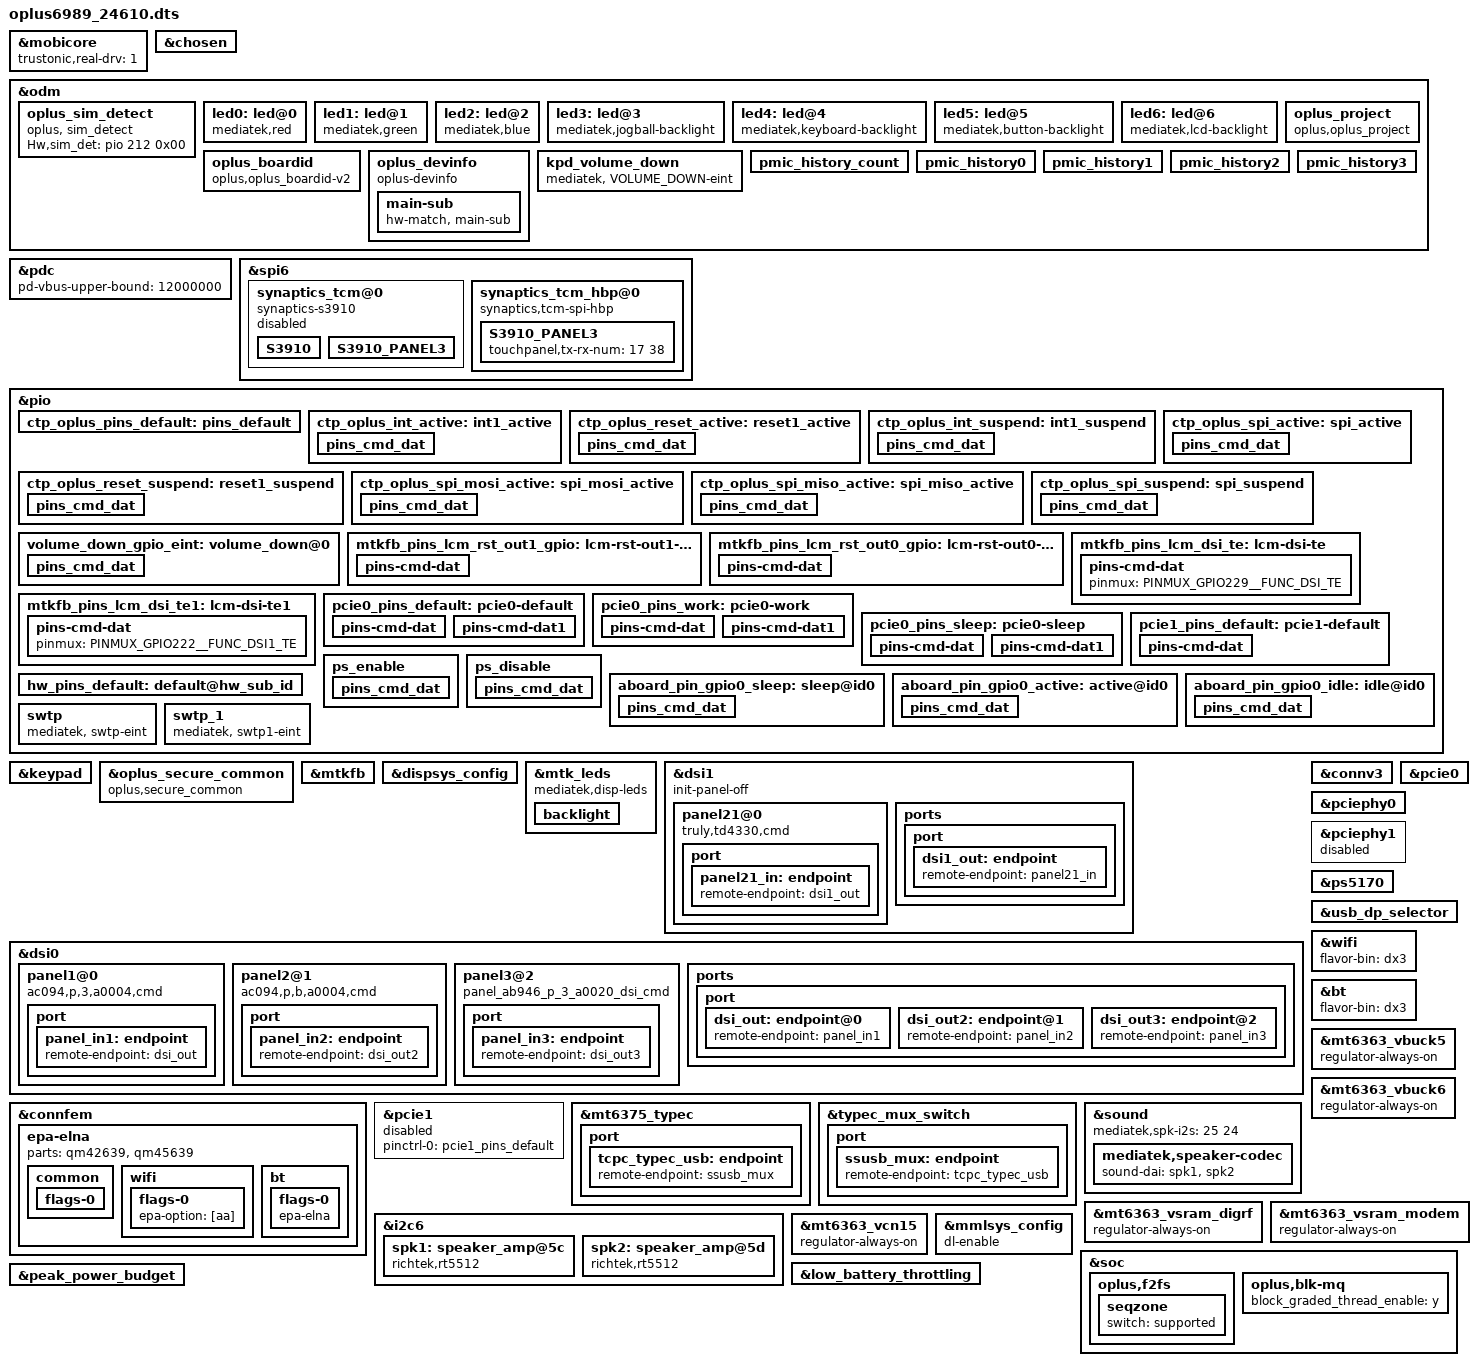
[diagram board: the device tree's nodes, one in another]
// SPDX-License-Identifier: (GPL-2.0 OR MIT)
/*
 * Copyright (C) 2022 MediaTek Inc.
 */
/dts-v1/;
/plugin/;
#include <dt-bindings/interrupt-controller/arm-gic.h>
#include <dt-bindings/interrupt-controller/irq.h>
#include <dt-bindings/pinctrl/mt6989-pinfunc.h>
#include <dt-bindings/phy/phy.h>
//#ifdef OPLUS_BUG_STABILITY
//NFC dtsi
#include "mediatek/nfc/mt6989_24610_sn220.dtsi"
//endif OPLUS_BUG_STABILITY

/* #ifdef OPLUS_FEATURE_CHG_BASIC */
/* Add for DX-3 charge device-tree */
#include "mediatek/oplus_misc_24610.dtsi"
/* #endif */

//#ifdef OPLUS_FEATURE_SENSOR
#include "mediatek/oplus_sensor_24610.dtsi"
//#endif

/* #ifdef OPLUS_FEATURE_CHG_BASIC */
#include "mediatek/oplus_charge_24610.dtsi"
/* #endif */

/* Trustonic Mobilecore real driver */
&mobicore{
        trustonic,real-drv = <1>;
};

/* Add for Cayman(24610) fingerprint device-tree */
/* #ifdef CONFIG_UFF_FINGERPRINT */
#include "mediatek/oplus_uff_24610.dtsi"
/* #endif CONFIG_UFF_FINGERPRINT */

&chosen {
bootargs_ext = "kmemleak=off kasan=off \
loglevel=8 initcall_debug=1 \
log_buf_len=2m \
arm64.nopauth arm64.nosme arm64.nosve";
};

&odm {
/* Add for sim detect */
    oplus_sim_detect {
        compatible = "oplus, sim_detect";
        Hw,sim_det = <&pio 212 0x00>;
    };
};

/* #ifdef OPLUS_DISPLAY_FEATURE */
&odm {
	led0:led@0 {
		compatible = "mediatek,red";
		led_mode = <0>;
		data = <1>;
		pwm_config = <0 0 0 0 0>;
	};
	led1:led@1 {
		compatible = "mediatek,green";
		led_mode = <0>;
		data = <1>;
		pwm_config = <0 0 0 0 0>;
	};
	led2:led@2 {
		compatible = "mediatek,blue";
		led_mode = <0>;
		data = <1>;
		pwm_config = <0 0 0 0 0>;
	};
	led3:led@3 {
		compatible = "mediatek,jogball-backlight";
		led_mode = <0>;
		data = <1>;
		pwm_config = <0 0 0 0 0>;
	};
	led4:led@4 {
		compatible = "mediatek,keyboard-backlight";
		led_mode = <0>;
		data = <1>;
		pwm_config = <0 0 0 0 0>;
	};
	led5:led@5 {
		compatible = "mediatek,button-backlight";
		led_mode = <0>;
		data = <1>;
		pwm_config = <0 0 0 0 0>;
	};
	led6:led@6 {
		compatible = "mediatek,lcd-backlight";
		led_mode = <4>;
		data = <1>;
		pwm_config = <0 1 0 0 0>;
	};
};

&pdc {
	pd-vbus-upper-bound = <12000000>;
};


&spi6 {
	status = "okay";
	#address-cells = <1>;
	#size-cells = <0>;

	synaptics_tcm@0{
		compatible = "synaptics-s3910";
		reg = <0x0>;
		chip-name = "S3910";
		status = "disabled";
		spi-max-frequency = <19000000>;
		/* Interrupt && Irq-gpio */
		interrupt-parent = <&pio>;
		interrupts = <6 0x2008>;

		/* Power Config */
		/* enable2v8_gpio  = <&pio 164 0x1>; */
		vdd_2v8-supply = <&mt6373_vtp>;
		vdd_2v8_volt = <3000000>;
		/* vcc_1v8-supply  = <&mt6373_vmc>; */
		/* vcc_1v8_volt = <1800000>; */

		/* Other HW Resource */

		irq-gpio = <&pio 6 0x2008>;
		reset-gpio = <&pio 3 0x1>;
		//cs-gpio = <&pio 110 0x00>;

		pinctrl-names = "default",  "oplus_int_active",
		"oplus_reset_active", "oplus_int_suspend",
		"oplus_reset_suspend", "oplus_spi_active",
		"oplus_spi_suspend";
		pinctrl-0 = <&ctp_oplus_pins_default>;
		pinctrl-1 = <&ctp_oplus_int_active>;
		pinctrl-2 = <&ctp_oplus_reset_active>;
		pinctrl-3 = <&ctp_oplus_int_suspend>;
		pinctrl-4 = <&ctp_oplus_reset_suspend>;
		pinctrl-5 = <&ctp_oplus_spi_active>, <&ctp_oplus_spi_mosi_active>;
		pinctrl-6 = <&ctp_oplus_spi_suspend>;

		touchpanel,max-num-support = <10>;
		touchpanel,tx-rx-num = <18 39>;
		touchpanel,panel-coords = <12640 27800>;
		touchpanel,display-coords = <1264 2780>;
		touchpanel,touchmajor-limit = <128 216>;
		touchpanel,elimination-range = <20 200 200>;
		touchpanel,int-mode = <1>; /*0: interrupt and disable, 1:interrupt and not disable*/
		touchpanel,smooth-level = <0 1 2 4 7 9>;
		touchpanel,smooth-level-charging = <0 2 4 7 8 9>;
		touchpanel,sensitive-level = <0 70 55 40 25 10>;
		touchpanel,single-optimized-time = <8>;
		touchpanel,high-frame-rate-time = <60>;

		vid_len = <2>;
		panel_type = <7 3>; /*type:7 TIANMA*/
		platform_support_project = <24610 24708>;
		platform_support_project_dir = <24610 24610>;
		platform_support_project_commandline = "panel_ab948_p_7_a0020_dsi_cmd", "panel_ab946_p_3_a0020_dsi_cmd";

		prevention,curved_screen_V2;
		prevention,grip_disable_level = <6>;
		prevention,updelay_time_ms = <30>;
		prevention,makeup_cnt_weight = <4 1 2 2 2>;
		prevention,large_corner_range = <1380 3400>;
		prevention,large_corner_judge_condition = <500 300 1000 7 7>;
		prevention,trx_reject_condition = <8 7 7>;
		prevention,trx_strict_reject_condition = <8 6 6>;
		prevention,large_judge_time_ms = <500 50 30>;
		prevention,large_exit_condition = <8 8 2>;
		prevention,single_channel_width = <320 320>;
		prevention,normal_tap_condition = <10 350>;
		prevention,long_edge_condition = <179 90 120 80>;
		prevention,long_strict_edge_condition = <160 60>;
		prevention,long_fingerhold_condition = <70 6 4 4>;
		prevention,short_edge_condition = <179 90 120 80>;
		prevention,short_strict_edge_condition = <160 60>;
		prevention,large_strict_exit_condition = <6 6>;
		prevention,top_corner_config = <250 750 1000>;
		prevention,edge_swipe_config = <340 1130>;

		prevention,curved_screen_V4;
		prevention,long_eliminate_point_type = <2 12400 9240 240 27720 300 1>;
		prevention,long_fingerhold_condition2 = <700 2000 0 0>;
		prevention,top_corner_config2 =<3 80 600 1500 0>;
		prevention,hor_long_top_corner_config =<300 2000 0 0>;
		prevention,top_middle_config =<12400 1000 1000 0>;
		prevention,corner_eliminate_point_type =<0 1380 2270 1>;
		prevention,finger_hold_differ_size = <1 0 400 300>;
		prevention,finger_hold_max_rx_exit_distance = <5 350 2300>;
		prevention,max_rx_exit_distance = <1 5 150 350 2000>;
		prevention,dynamic_finger_hold_exit_distance = <1 350 2300 450>;
		prevention,edge_sliding_matched_support = <1 150 3 0>;

		//grip v4.2 reclining mode
		prevention,reclining_mode_support = <1>;
		prevention,long_eliminate_point_type_recli = <2 12400 9240 240 27720 500 1>;
		prevention,finger_hold_differ_size_recli = <1 0 400 400>;
		prevention,finger_hold_max_rx_exit_distance_recli = <5 350 2300>;
		prevention,max_rx_exit_distance_recli = <1 5 100 350 2300>;
		prevention,dynamic_finger_hold_exit_distance_recli = <1 350 2300 450>;
		prevention,edge_sliding_matched_support_recli = <1 150 3 0>;
		prevention,long_edge_condition_recli = <179 90 120 80>;

		/* SW Support Feature Control */
		black_gesture_support;
		sportify_aod_gesture_support;
		pressure_report_support;
		charger_pump_support;
		game_switch_support;
		glove_mode_support;
		smart_gesture_support;
		fw_update_app_support;
		fingerprint_underscreen_support;
		freq_hop_simulate_support;
		report_flow_unlock_support;
		screenoff_fingerprint_info_support;
		irq_need_dev_resume_ok;
		enable_point_auto_change;
		kernel_grip_support;
		//grip_no_driver_support;
		health_monitor_support;
		black_gesture_indep_support;
		snr_read_support;
		palm_to_sleep_support;
		exception_upload_support;
		tp_data_record_support;
		fingerprint_not_report_in_suspend;
		/*
		 *Virtual Key Config:
		 *1:touchpanel,button-type: <virtualkey_type  supportted_button-map>
		 *virtualkey_type:
		 *Type 1: using board_properties
		 *Type 2: using same IC (button zone&& touch zone are seprate)
		 *Type 3: using diffrent IC (button zone&& touch zone are seprate)
		 *Type 4: No need of virtual key process
		 *supportted_button-map:select|menu|home|back
		 *
		 *2:touchpanel,button-map
		 *type (X1,Y1)(X2,Y2)(X3,Y3)(Width_X,Hight_Y)--Only when button-type is 0
		 */
		touchpanel,button-type = <4>;
		touchpanel.button-TRx = <0 0>;

		S3910 {
			switch_report_rate;
			report_rate_default = <60>;
			report_rate_game_value = <0x03>;
			fps_report_rate = <60 2 90 3 120 3>;//1:360Hz 2:125Hz 3:240Hz
			fwupdate_bootloader = <1>;
			normal_config_version = <2>;
			default_gesture_mask = <8191>;
		};
		S3910_PANEL3 {
			interrupt-parent = <&pio>;
			interrupts = <6 0x2008>;

			/* Power Config */
			/* enable2v8_gpio  = <&pio 164 0x1>; */
			vdd_2v8-supply = <&mt6373_vtp>;
			vdd_2v8_volt = <3000000>;
			/* vcc_1v8-supply  = <&mt6373_vmc>; */
			/* vcc_1v8_volt = <1800000>; */

			/* Other HW Resource */

			irq-gpio = <&pio 6 0x2008>;
			reset-gpio = <&pio 3 0x1>;
			//cs-gpio = <&pio 110 0x00>;

			pinctrl-names = "default",  "oplus_int_active",
			"oplus_reset_active", "oplus_int_suspend",
			"oplus_reset_suspend", "oplus_spi_active",
			"oplus_spi_suspend";
			pinctrl-0 = <&ctp_oplus_pins_default>;
			pinctrl-1 = <&ctp_oplus_int_active>;
			pinctrl-2 = <&ctp_oplus_reset_active>;
			pinctrl-3 = <&ctp_oplus_int_suspend>;
			pinctrl-4 = <&ctp_oplus_reset_suspend>;
			pinctrl-5 = <&ctp_oplus_spi_active>, <&ctp_oplus_spi_mosi_active>;
			pinctrl-6 = <&ctp_oplus_spi_suspend>;

			touchpanel,max-num-support = <10>;
			touchpanel,tx-rx-num = <17 38>;
			touchpanel,panel-coords = <12640 27800>;
			touchpanel,display-coords = <1264 2780>;
			touchpanel,touchmajor-limit = <128 216>;
			touchpanel,elimination-range = <20 200 200>;
			touchpanel,int-mode = <1>; /*0: interrupt and disable, 1:interrupt and not disable*/
			touchpanel,smooth-level = <0 1 2 4 7 9>;
			touchpanel,smooth-level-charging = <0 2 4 7 8 9>;
			touchpanel,sensitive-level = <0 70 55 40 25 10>;
			touchpanel,single-optimized-time = <8>;
			touchpanel,high-frame-rate-time = <60>;

			prevention,curved_screen_V2;
			prevention,grip_disable_level = <6>;
			prevention,updelay_time_ms = <30>;
			prevention,makeup_cnt_weight = <4 1 2 2 2>;
			prevention,large_corner_range = <1380 3400>;
			prevention,large_corner_judge_condition = <500 300 1000 7 7>;
			prevention,trx_reject_condition = <8 7 7>;
			prevention,trx_strict_reject_condition = <8 6 6>;
			prevention,large_judge_time_ms = <500 50 30>;
			prevention,large_exit_condition = <8 8 2>;
			prevention,single_channel_width = <320 320>;
			prevention,normal_tap_condition = <10 350>;
			prevention,long_edge_condition = <179 90 120 80>;
			prevention,long_strict_edge_condition = <160 60>;
			prevention,long_fingerhold_condition = <70 6 4 4>;
			prevention,short_edge_condition = <179 90 120 80>;
			prevention,short_strict_edge_condition = <160 60>;
			prevention,large_strict_exit_condition = <6 6>;
			prevention,top_corner_config = <250 750 1000>;
			prevention,edge_swipe_config = <340 1130>;

			prevention,curved_screen_V4;
			prevention,long_eliminate_point_type = <2 12400 9240 240 27720 300 1>;
			prevention,long_fingerhold_condition2 = <700 2000 0 0>;
			prevention,top_corner_config2 =<3 80 600 1500 0>;
			prevention,hor_long_top_corner_config =<300 2000 0 0>;
			prevention,top_middle_config =<12400 1000 1000 0>;
			prevention,corner_eliminate_point_type =<0 1380 2270 1>;
			prevention,finger_hold_differ_size = <1 0 400 300>;
			prevention,finger_hold_max_rx_exit_distance = <5 350 2300>;
			prevention,max_rx_exit_distance = <1 5 150 350 2000>;
			prevention,dynamic_finger_hold_exit_distance = <1 350 2300 450>;
			prevention,edge_sliding_matched_support = <1 150 3 0>;
		};
	};

	synaptics_tcm_hbp@0{
		compatible = "synaptics,tcm-spi-hbp";
		reg = <0x0>;
		chip-name = "S3910";
		status = "okay";
		spi-max-frequency = <19000000>;

		/* Interrupt && Irq-gpio */
		interrupt-parent = <&pio>;
		interrupts = <6 0x2008>;

		/* Power Config */
		/* enable2v8_gpio  = <&pio 164 0x1>; */
		/* synaptics,avdd-gpio = <&pio 186 0x1>; */
		avdd-supply = <&mt6373_vtp>;
		synaptics,avdd-name = "avdd";
		/* vcc_1v8-supply  = <&mt6373_vmc>; */
		/* vcc_1v8_volt = <1800000>; */



		/* Other HW Resource */

		synaptics,irq-gpio = <&pio 6 0x2008>;
		synaptics,reset-gpio = <&pio 3 0x1>;
		//cs-gpio = <&pio 110 0x00>;


		pinctrl-names = "default", "ts_spi_active", "ts_spi_suspend";
		pinctrl-0 = <&ctp_oplus_pins_default>;
		pinctrl-1 = <&ctp_oplus_int_active &ctp_oplus_reset_active &ctp_oplus_spi_active &ctp_oplus_spi_mosi_active &ctp_oplus_spi_miso_active>;
		pinctrl-2 = <&ctp_oplus_int_suspend &ctp_oplus_reset_suspend &ctp_oplus_spi_suspend>;

		touchpanel,max-num-support = <10>;
		touchpanel,tx-rx-num = <18 39>;
		touchpanel,panel-coords = <20224 44480>;
		vid_len = <2>;
		panel_type = <7 3>; /*type:7 TIANMA*/
		platform_support_project = <24610 24708>;
		platform_support_project_dir = <24610 24610>;
		platform_support_project_commandline = "panel_ab948_p_7_a0020_dsi_cmd", "panel_ab946_p_3_a0020_dsi_cmd";

		synaptics,power-on-state = <1>;
		synaptics,power-delay-ms = <200>;
		synaptics,irq-on-state = <0>;
		synaptics,reset-on-state = <0>;
		synaptics,reset-active-ms = <10>;
		synaptics,reset-delay-ms = <80>;
		synaptics,spi-mode = <0>;
		synaptics,spi-byte-delay-us = <0>;
		synaptics,spi-block-delay-us = <0>;

		stats_upload_support;

		S3910_PANEL3 {
			touchpanel,tx-rx-num = <17 38>;
		};
	};
};

/*add for nvwa TP*/
&pio {
	ctp_oplus_pins_default: pins_default {
	};
	ctp_oplus_int_active: int1_active {
		pins_cmd_dat {
			pinmux = <PINMUX_GPIO6__FUNC_GPIO6>;
			bias-disable;
			input-enable;
		};
	};
	ctp_oplus_reset_active: reset1_active {
		pins_cmd_dat {
			pinmux = <PINMUX_GPIO3__FUNC_GPIO3>;
			output-high;
		};
	};
	ctp_oplus_int_suspend: int1_suspend {
		pins_cmd_dat {
			pinmux = <PINMUX_GPIO6__FUNC_GPIO6>;
			output-low;
		};
	};
	ctp_oplus_reset_suspend: reset1_suspend {
		pins_cmd_dat {
			pinmux = <PINMUX_GPIO3__FUNC_GPIO3>;
			output-low;
		};
	};
	ctp_oplus_spi_active: spi_active {
		pins_cmd_dat {
			pinmux = <PINMUX_GPIO232__FUNC_SPI6_B_CSB>,
				<PINMUX_GPIO231__FUNC_SPI6_B_CLK>;
			bias-disable;
			drive-strength = <2>;
		};
	};
	ctp_oplus_spi_mosi_active: spi_mosi_active {
		pins_cmd_dat {
			pinmux = <PINMUX_GPIO233__FUNC_SPI6_B_MO>;
			bias-disable;
			drive-strength = <3>;
		};
	};
	ctp_oplus_spi_miso_active: spi_miso_active {
		pins_cmd_dat {
			pinmux = <PINMUX_GPIO234__FUNC_SPI6_B_MI>;
			bias-disable;
			drive-strength = <2>;
		};
	};
	ctp_oplus_spi_suspend: spi_suspend {
		pins_cmd_dat {
			pinmux = < PINMUX_GPIO234__FUNC_GPIO234>,
				< PINMUX_GPIO232__FUNC_GPIO232>,
				<PINMUX_GPIO233__FUNC_GPIO233>,
				< PINMUX_GPIO231__FUNC_GPIO231>;
			bias-disable;
			output-low;
			drive-strength = <4>;
		};
	};
};


&keypad {
        keypad,volume-down = <&pio 11 0x00>;
        pinctrl-names = "volume_down_as_int";
        pinctrl-0 = <&volume_down_gpio_eint>;
        status = "okay";
};

&pio {
        volume_down_gpio_eint:volume_down@0{
                pins_cmd_dat {
                        pinmux = <PINMUX_GPIO11__FUNC_GPIO11>;
                        slew-rate = <0>;  /*direction 0:in, 1:out*/
                        input-enable;
                        bias-disable;
                };
        };
};

&oplus_secure_common {
    compatible = "oplus,secure_common";
    oplus,sec_reg_num = <0>;
    oplus,sec_en_anti_reg = <0>;
    oplus,sec_override1_reg = <0>;
    oplus,override1_en_value = <0>;
};

&pio {
	mtkfb_pins_lcm_rst_out1_gpio: lcm-rst-out1-gpio {
		pins-cmd-dat {
			pinmux = <PINMUX_GPIO230__FUNC_GPIO230>;
			slew-rate = <1>;
			output-high;
		};
	};

	mtkfb_pins_lcm_rst_out0_gpio: lcm-rst-out0-gpio {
		pins-cmd-dat {
			pinmux = <PINMUX_GPIO230__FUNC_GPIO230>;
			slew-rate = <1>;
			output-low;
		};
	};
	mtkfb_pins_lcm_dsi_te: lcm-dsi-te {
		pins-cmd-dat {
			pinmux = <PINMUX_GPIO229__FUNC_DSI_TE>;
		};
	};

	mtkfb_pins_lcm_dsi_te1: lcm-dsi-te1 {
		pins-cmd-dat {
			pinmux = <PINMUX_GPIO222__FUNC_DSI1_TE>;
		};
	};

};

&mtkfb {
	pinctrl-names = "lcm_rst_out1_gpio", "lcm_rst_out0_gpio",
		"mode_te_te", "mode_te_te1";
	pinctrl-0 = <&mtkfb_pins_lcm_rst_out1_gpio>;
	pinctrl-1 = <&mtkfb_pins_lcm_rst_out0_gpio>;
	pinctrl-2 = <&mtkfb_pins_lcm_dsi_te>;
	pinctrl-3 = <&mtkfb_pins_lcm_dsi_te1>;

	status = "okay";
};

&dispsys_config {
	pinctrl-names = "mode_te_te", "mode_te_te1";
	pinctrl-0 = <&mtkfb_pins_lcm_dsi_te>;
	pinctrl-1 = <&mtkfb_pins_lcm_dsi_te1>;
	status = "okay";
};

/*  OPLUS_DISPLAY_FEATURE */
&mtk_leds {
	compatible = "mediatek,disp-leds";
	status = "okay";

	backlight {
		label = "lcd-backlight";
		led_mode = <4>;
		min-brightness = <1>;
		max-brightness = <4094>;
		max-hw-brightness = <4094>;
		led-bits = <13>;
		trans-bits = <13>;
		default-state = "on";
	};
};
/*  OPLUS_DISPLAY_FEATURE */

&dsi1 {
//	status = "okay";
	#address-cells = <1>;
	#size-cells = <0>;
	init-panel-off;
	panel21@0 {
		compatible = "truly,td4330,cmd";
		reg = <1>;
		pm-enable-gpios = <&pio 215 0>;
		reset-gpios = <&pio 230 0>;
		gate-ic = <4831>;
		pinctrl-names = "default";
		port {
			panel21_in: endpoint {
				remote-endpoint = <&dsi1_out>;
			};
		};
	};
	ports {
		port {
			dsi1_out: endpoint {
				remote-endpoint = <&panel21_in>;
			};
		};
	};
};

&dsi0 {
	status = "okay";
	#address-cells = <1>;
	#size-cells = <0>;
	/** #ifdef OPLUS_DISPLAY_FEATURE **/
	panel1@0 {
		compatible = "ac094,p,3,a0004,cmd";
		reg = <0>;
		pm-enable-gpios = <&pio 86 0>;
		reset-gpios = <&pio 230 0>;
		1p8-supply = <&mt6373_vrfio18_aif>;
		3p0-supply = <&mt6373_vmc>;
		oplus,dsi-serial-number-enabled=<1>;
		oplus,dsi-serial-number-switch-page;
		oplus,dsi-serial-number-index= <0>;
		oplus,dsi-serial-number-switch-page-command= <0xFF 0x08 0x38 0x1D>;
		oplus,dsi-serial-number-default-switch-page-command= <0xFF 0x08 0x38 0x00>;
		oplus,dsi-serial-number-reg= <0x82>;
		oplus,dsi-serial-number-read-count= <7>;
		oplus,panel-max-brightness=<4094>;
		/* 0 not support, 1 with switch, 2 Global high frequency pwm without switch */
		oplus,pwm-turbo-support = <2>;
		oplus,pwm-switch-backlight-threshold = <0x43F>;
		oplus,pwm-onepulse-support = <1>;
		oplus,pwm-onepulse-enabled = <0>;
		oplus,pwm-turbo-wait-te = <1>;
		oplus-adfr-config = <0x201>;
		oplus-adfr-test-te-gpios = <&pio 222 0>;
		/* ofp config */
		oplus,ofp-fp-type = <0x10>;
		oplus,ofp-fp-type-compatible-mode;
		oplus,ofp-need-to-update-lhbm-pressed-icon-gamma;
		oplus,ofp-lhbm-dbv-alpha-cmd-index = <1>;
		oplus,ofp-lhbm-dbv-alpha-register-offset = <1>;
		oplus,ofp-lhbm-dbv-alpha-value = <
			/* lhbm dbv alpha value from 0 to 1087 */
			0x0CC 0x0CC 0x0CC 0x0CC 0x0CC 0x0CC 0x0CC 0x0CC 0x0CC 0x0CC 0x0CC 0x0CC 0x0CC 0x0CC 0x0CC 0x0CC 0x0CC 0x0CC 0x0CC 0x0CC
			0x0CC 0x0CC 0x0CC 0x0CC 0x0CC 0x0CC 0x0CC 0x0CC 0x0CC 0x0CC 0x0CC 0x0CC 0x0CC 0x0CC 0x0CC 0x0CC 0x0CC 0x0CC 0x0CC 0x0CC
			0x0CC 0x0CD 0x0CD 0x0CE 0x0CE 0x0CF 0x0D0 0x0D0 0x0D0 0x0D1 0x0D0 0x0D1 0x0D2 0x0D2 0x0D2 0x0D3 0x0D3 0x0D4 0x0D4 0x0D4
			0x0D4 0x0D5 0x0D5 0x0D5 0x0D6 0x0D6 0x0D6 0x0D6 0x0D7 0x0D7 0x0D7 0x0D8 0x0D9 0x0D9 0x0D9 0x0DA 0x0DA 0x0DA 0x0DB 0x0DB
			0x0DC 0x0DC 0x0DD 0x0DD 0x0DE 0x0DE 0x0DE 0x0DE 0x0DF 0x0DF 0x0E0 0x0E0 0x0E1 0x0E1 0x0E2 0x0E2 0x0E3 0x0E3 0x0E3 0x0E4
			0x0E4 0x0E5 0x0E5 0x0E5 0x0E6 0x0E6 0x0E6 0x0E7 0x0E7 0x0E8 0x0E8 0x0E9 0x0E9 0x0E9 0x0EA 0x0EA 0x0EA 0x0EB 0x0EB 0x0EC
			0x0EC 0x0ED 0x0ED 0x0EE 0x0EE 0x0EF 0x0EF 0x0EF 0x0F0 0x0F0 0x0F1 0x0F2 0x0F1 0x0F2 0x0F3 0x0F3 0x0F4 0x0F4 0x0F5 0x0F5
			0x0F6 0x0F6 0x0F7 0x0F7 0x0F8 0x0F8 0x0F8 0x0F9 0x0F9 0x0FA 0x0FA 0x0FB 0x0FC 0x0FC 0x0FC 0x0FD 0x0FD 0x0FD 0x0FD 0x0FF
			0x0FF 0x100 0x101 0x101 0x101 0x102 0x102 0x102 0x102 0x104 0x104 0x104 0x105 0x105 0x106 0x107 0x108 0x108 0x107 0x109
			0x109 0x109 0x10A 0x10B 0x10B 0x10C 0x10C 0x10C 0x10E 0x10E 0x10E 0x10F 0x110 0x110 0x111 0x111 0x111 0x111 0x112 0x113
			0x114 0x115 0x115 0x115 0x116 0x116 0x117 0x116 0x118 0x119 0x119 0x119 0x11A 0x11A 0x11B 0x11C 0x11D 0x11B 0x11E 0x11E
			0x11E 0x11F 0x11F 0x120 0x120 0x121 0x122 0x122 0x123 0x124 0x124 0x125 0x125 0x126 0x126 0x127 0x126 0x128 0x129 0x129
			0x12A 0x12A 0x12B 0x12C 0x12C 0x12D 0x12C 0x12E 0x12F 0x12F 0x130 0x130 0x131 0x132 0x132 0x133 0x132 0x134 0x134 0x134
			0x135 0x135 0x136 0x137 0x137 0x137 0x137 0x13A 0x13A 0x13B 0x13C 0x13C 0x13C 0x13D 0x13D 0x13D 0x13F 0x140 0x140 0x141
			0x143 0x143 0x143 0x144 0x144 0x144 0x146 0x147 0x147 0x148 0x149 0x149 0x149 0x14B 0x14C 0x14B 0x14C 0x14D 0x14E 0x14F
			0x150 0x150 0x151 0x151 0x152 0x151 0x154 0x155 0x155 0x156 0x157 0x157 0x158 0x159 0x159 0x158 0x15B 0x15B 0x15B 0x15C
			0x15E 0x15F 0x15E 0x160 0x15F 0x161 0x161 0x163 0x163 0x164 0x164 0x166 0x166 0x168 0x168 0x169 0x16A 0x16A 0x16B 0x16B
			0x16C 0x16D 0x16E 0x16E 0x16E 0x16F 0x171 0x172 0x173 0x173 0x174 0x174 0x175 0x175 0x176 0x178 0x178 0x179 0x179 0x17B
			0x17C 0x17D 0x17D 0x17E 0x17E 0x180 0x181 0x181 0x181 0x182 0x183 0x184 0x184 0x185 0x187 0x189 0x189 0x18A 0x18A 0x18B
			0x18C 0x18D 0x18D 0x18D 0x18E 0x190 0x191 0x193 0x193 0x194 0x194 0x195 0x196 0x196 0x198 0x198 0x199 0x199 0x19A 0x19D
			0x19D 0x19D 0x19F 0x19F 0x1A0 0x1A1 0x1A1 0x1A2 0x1A3 0x1A4 0x1A4 0x1A5 0x1A6 0x1A7 0x1A9 0x1A9 0x1A9 0x1AA 0x1AD 0x1AD
			0x1AE 0x1AD 0x1AF 0x1B0 0x1B0 0x1B0 0x1B2 0x1B2 0x1B2 0x1B3 0x1B6 0x1B6 0x1B7 0x1B7 0x1B8 0x1B9 0x1B9 0x1B8 0x1BA 0x1BC
			0x1BC 0x1BD 0x1BE 0x1BF 0x1BF 0x1C0 0x1C2 0x1C2 0x1C3 0x1C2 0x1C5 0x1C6 0x1C6 0x1C5 0x1C8 0x1CA 0x1CA 0x1CA 0x1CB 0x1CB
			0x1CC 0x1CD 0x1CF 0x1CF 0x1CF 0x1CF 0x1D1 0x1D2 0x1D3 0x1D3 0x1D5 0x1D6 0x1D6 0x1D7 0x1D7 0x1D8 0x1D9 0x1DA 0x1DA 0x1DB
			0x1DC 0x1DD 0x1DD 0x1E0 0x1E1 0x1E0 0x1E1 0x1E3 0x1E4 0x1E4 0x1E3 0x1E6 0x1E6 0x1E8 0x1E8 0x1E9 0x1E9 0x1EA 0x1EA 0x1ED
			0x1ED 0x1EE 0x1ED 0x1F0 0x1F1 0x1F2 0x1F2 0x1F3 0x1F4 0x1F5 0x1F6 0x1F6 0x1F7 0x1F7 0x1F9 0x1FB 0x1FB 0x1FC 0x1FB 0x1FE
			0x1FF 0x200 0x1FF 0x201 0x201 0x203 0x203 0x205 0x206 0x206 0x207 0x208 0x209 0x209 0x209 0x20A 0x20C 0x20D 0x20D 0x20D
			0x20F 0x211 0x211 0x212 0x213 0x214 0x214 0x215 0x216 0x217 0x218 0x219 0x21A 0x21B 0x21B 0x21B 0x21E 0x21E 0x21F 0x21F
			0x222 0x221 0x223 0x224 0x225 0x225 0x225 0x226 0x229 0x229 0x229 0x229 0x22B 0x22D 0x22E 0x22D 0x22E 0x22F 0x231 0x232
			0x234 0x235 0x235 0x236 0x238 0x238 0x239 0x239 0x23A 0x23C 0x23C 0x23B 0x23E 0x23F 0x241 0x242 0x240 0x243 0x244 0x246
			0x246 0x246 0x247 0x249 0x249 0x24A 0x24B 0x24C 0x24C 0x24F 0x250 0x251 0x250 0x252 0x253 0x255 0x254 0x256 0x257 0x258
			0x258 0x25B 0x25B 0x25B 0x25B 0x25D 0x25E 0x25F 0x25F 0x261 0x261 0x263 0x264 0x265 0x266 0x266 0x266 0x268 0x26A 0x26A
			0x26B 0x26D 0x26F 0x26F 0x270 0x271 0x272 0x272 0x272 0x274 0x276 0x277 0x277 0x279 0x27A 0x27A 0x27B 0x27C 0x27D 0x27F
			0x27E 0x280 0x281 0x281 0x283 0x283 0x285 0x285 0x285 0x287 0x289 0x289 0x289 0x28B 0x28C 0x28C 0x28D 0x28D 0x28E 0x28F
			0x290 0x291 0x292 0x293 0x295 0x294 0x295 0x297 0x296 0x298 0x29A 0x29A 0x29B 0x29B 0x29D 0x29E 0x29F 0x29F 0x2A0 0x2A1
			0x2A2 0x2A2 0x2A4 0x2A4 0x2A6 0x2A7 0x2A7 0x2A8 0x2A8 0x2A9 0x2AA 0x2AC 0x2AC 0x2AC 0x2AF 0x2B0 0x2B0 0x2B1 0x2B2 0x2B2
			0x2B4 0x2B5 0x2B6 0x2B7 0x2B8 0x2B8 0x2B8 0x2B9 0x2BA 0x2BC 0x2BC 0x2BD 0x2BE 0x2C0 0x2BF 0x2C2 0x2C1 0x2C3 0x2C4 0x2C4
			0x2C6 0x2C7 0x2C7 0x2C7 0x2C7 0x2CA 0x2CB 0x2CC 0x2CC 0x2CD 0x2CE 0x2CF 0x2D0 0x2D0 0x2D0 0x2D3 0x2D4 0x2D3 0x2D5 0x2D7
			0x2D7 0x2D9 0x2DA 0x2D8 0x2DB 0x2DC 0x2DC 0x2DD 0x2DF 0x2E0 0x2E1 0x2E1 0x2E2 0x2E2 0x2E3 0x2E4 0x2E6 0x2E6 0x2E7 0x2E9
			0x2EA 0x2EA 0x2EB 0x2EC 0x2EE 0x2EE 0x2EF 0x2EE 0x2F1 0x2F1 0x2F2 0x2F4 0x2F4 0x2F5 0x2F6 0x2F7 0x2F8 0x2F9 0x2FA 0x2FB
			0x2FD 0x2FD 0x2FC 0x2FF 0x300 0x2FF 0x2FF 0x2FF 0x2FF 0x303 0x305 0x306 0x307 0x308 0x309 0x308 0x308 0x30C 0x30C 0x30C
			0x30E 0x30F 0x310 0x311 0x312 0x312 0x313 0x313 0x314 0x315 0x317 0x318 0x318 0x318 0x319 0x31B 0x31C 0x31D 0x31E 0x31E
			0x320 0x321 0x321 0x320 0x324 0x325 0x326 0x327 0x327 0x329 0x32A 0x32B 0x32A 0x32C 0x32E 0x32E 0x32D 0x32F 0x331 0x331
			0x333 0x334 0x334 0x334 0x335 0x337 0x338 0x338 0x339 0x33A 0x33B 0x33B 0x33C 0x33C 0x33D 0x33E 0x341 0x342 0x343 0x343
			0x345 0x345 0x346 0x347 0x348 0x34B 0x349 0x34B 0x34C 0x34D 0x34F 0x34E 0x351 0x350 0x350 0x354 0x354 0x354 0x356 0x357
			0x358 0x358 0x359 0x359 0x359 0x35A 0x35D 0x35E 0x35F 0x360 0x360 0x360 0x361 0x362 0x364 0x366 0x366 0x367 0x368 0x369
			0x36A 0x36B 0x36C 0x36D 0x36E 0x36F 0x370 0x371 0x371 0x371 0x372 0x375 0x376 0x377 0x378 0x379 0x37B 0x37B 0x37C 0x37D
			0x37D 0x37F 0x37F 0x380 0x381 0x382 0x382 0x385 0x385 0x386 0x387 0x388 0x388 0x389 0x38A 0x38B 0x38D 0x38E 0x38E 0x38F
			0x391 0x391 0x392 0x393 0x394 0x395 0x395 0x396 0x397 0x398 0x39A 0x39B 0x39C 0x39D 0x39D 0x39E 0x3A0 0x3A0 0x3A0 0x3A2
			0x3A3 0x3A3 0x3A4 0x3A5 0x3A6 0x3A7 0x3A7 0x3A8 0x3AA 0x3AB 0x3AB 0x3AE 0x3AE 0x3AE 0x3B0 0x3B0 0x3B0 0x3B1 0x3B3 0x3B4
			0x3B5 0x3B6 0x3B6 0x3B8 0x3B8 0x3B9 0x3BB 0x3BC 0x3BC 0x3BE 0x3BE 0x3C0 0x3C0 0x3C1 0x3C2 0x3C3 0x3C3 0x3C5 0x3C6 0x3C6
			0x3C8 0x3C8 0x3C9 0x3CA 0x3CB 0x3CB 0x3CD 0x3CE 0x3CE 0x3D0 0x3D0 0x3D2 0x3D3 0x3D3 0x3D4 0x3D5 0x3D6 0x3D6 0x3D8 0x3D9
			0x3D9 0x3DB 0x3DC 0x3DD 0x3DE 0x3DE 0x3DF 0x3E0 0x3E1 0x3E2 0x3E3 0x3E4 0x3E5 0x3E6 0x3E7 0x3E8 0x3E9 0x3E9 0x3EB 0x3EC
			0x3EC 0x3EE 0x3EE 0x3EF 0x3F1 0x3F1 0x3F2 0x3F3 0x3F4 0x3F4 0x3F7 0x3F7 0x3F8 0x3F9 0x3FA 0x3FA 0x3FB 0x3FB 0x3FC 0x3FE
			0x3FF 0x400 0x400 0x400 0x400 0x400 0x400 0x400
		>;
		res-switch = <2>;
		pinctrl-names = "default";
		port {
			panel_in1: endpoint {
				remote-endpoint = <&dsi_out>;
			};
		};
	};
	panel2@1 {
		compatible = "ac094,p,b,a0004,cmd";
		reg = <1>;
		pm-enable-gpios = <&pio 86 0>;
		reset-gpios = <&pio 230 0>;
		1p8-supply = <&mt6373_vrfio18_aif>;
		3p0-supply = <&mt6373_vmc>;
		oplus,dsi-serial-number-enabled=<1>;
		oplus,dsi-serial-number-switch-page;
		oplus,dsi-serial-number-index= <0>;
		oplus,dsi-serial-number-switch-page-command= <0xFF 0x08 0x38 0x00>;
		oplus,dsi-serial-number-default-switch-page-command= <0xFF 0x08 0x38 0x00>;
		oplus,dsi-serial-number-reg= <0xA1>;
		oplus,dsi-serial-number-read-count= <7>;
		/* 0 not support, 1 with switch, 2 Global high frequency pwm without switch */
		oplus,pwm-turbo-support = <2>;
		oplus,pwm-switch-backlight-threshold = <0x388>;
		oplus-adfr-config = <0x201>;
		oplus-adfr-test-te-gpios = <&pio 222 0>;
		/* ofp config */
		oplus,ofp-fp-type = <0x08>;
		res-switch = <2>;
		pinctrl-names = "default";
		port {
			panel_in2: endpoint {
				remote-endpoint = <&dsi_out2>;
			};
		};
	};
	panel3@2 {
		compatible = "panel_ab946_p_3_a0020_dsi_cmd";
		reg = <2>;
		reset-gpios = <&pio 230 0>;
		vddr_en-gpios = <&pio 86 0>;
		vddi-supply = <&mt6373_vrfio18_aif>;
		vci-supply = <&mt6373_vmc>;
		oplus,dsi-serial-number-enabled=<1>;
		oplus,dsi-serial-number-switch-page;
		oplus,dsi-serial-number-index= <0>;
		oplus,dsi-serial-number-switch-page-command= <0xFF 0x5A 0xA5 0x1D>;
		oplus,dsi-serial-number-default-switch-page-command= <0xFF 0x5A 0xA5 0x00>;
		oplus,dsi-serial-number-reg= <0x82>;
		oplus,dsi-serial-number-read-count= <7>;
		/* 0 not support, 1 with switch, 2 Global high frequency pwm without switch */
		oplus,pwm-turbo-support = <2>;
		oplus,pwm-switch-backlight-threshold = <0x48A>;
		oplus,pwm-onepulse-support = <1>;
		oplus,pwm-onepulse-enabled = <0>;
		oplus-adfr-config = <0x201>;
		oplus-adfr-test-te-gpios = <&pio 222 0>;
		/* ofp config */
		oplus,ofp-fp-type = <0x10>;
		res-switch = <2>;
		pinctrl-names = "default";
		port {
			panel_in3: endpoint {
				remote-endpoint = <&dsi_out3>;
			};
		};
	};

	/** #endif OPLUS_DISPLAY_FEATURE **/
	ports {
		port {
			dsi_out: endpoint@0 {
				remote-endpoint = <&panel_in1>;
			};

			dsi_out2: endpoint@1 {
				remote-endpoint = <&panel_in2>;
			};

			dsi_out3: endpoint@2 {
				remote-endpoint = <&panel_in3>;
			};
		};
	};
};

&connfem {
	/* Support Wifi & BT ePA/eLNA FEM on customer load */
	epa-elna {
		parts = <&qm42639 &qm45639>;

		common {
			flags-0 {
				rx-mode = [35];
				fe-ant-cnt = [82];
				fe-main-bt-share-lp2g = [80];
				fe-conn-spdt = [88];
				fe-reserved = [80];
			};
		};

		wifi {
			flags-0 {
				epa-option = [aa];
				/* open-loop; */
			};
		};

		bt {
			flags-0 {
				/* choose one of: epa-elna/epa/elna/bypass */
				epa-elna;
			};
		};
	};
};

/* #ifdef OPLUS_FEATURE_WIFI_SWITCH */
&connv3 {
	pinctrl-names = "connsys-pin-pmic-en-default",
					"connsys-pin-pmic-en-set",
					"connsys-pin-pmic-en-clr",
					"connsys-pin-pmic-faultb-default",
					"connsys-pin-pmic-faultb-enable",
					"connsys-combo-gpio-init",
					"connsys-combo-gpio-pre-on",
					"connsys-combo-gpio-on";
	pinctrl-0 = <&connsys_pin_pmic_en_default>;
	pinctrl-1 = <&connsys_pin_pmic_en_set>;
	pinctrl-2 = <&connsys_pin_pmic_en_clr>;
	pinctrl-3 = <&connsys_pin_pmic_faultb_default>;
	pinctrl-4 = <&connsys_pin_pmic_faultb_enable>;
	pinctrl-5 = <&connsys_combo_gpio_init>;
	pinctrl-6 = <&connsys_combo_gpio_pre_on>;
	pinctrl-7 = <&connsys_combo_gpio_on>;

	/delete-property/ pinctrl-8;
	/delete-property/ pinctrl-9;
};

&pio {
	/delete-node/ connsys_pin_pmic_vsel_low;
	/delete-node/ connsys_pin_pmic_vsel_high;
};
// #endif /* OPLUS_FEATURE_WIFI_SWITCH */

&pcie0 {
	pinctrl-names = "default", "sleep", "work";
	pinctrl-0 = <&pcie0_pins_default>;
	pinctrl-1 = <&pcie0_pins_sleep>;
	pinctrl-2 = <&pcie0_pins_work>;
	max-link-speed = <3>;
	status = "okay";
};

&pcie1 {
	pinctrl-names = "default";
	pinctrl-0 = <&pcie1_pins_default>;
	status = "disabled";
};

&pciephy0 {
	status = "okay";
};

&pciephy1 {
	status = "disabled";
};

/* PCIe pinmux start */
&pio {
	pcie0_pins_default: pcie0-default {
		pins-cmd-dat {
			pinmux = <PINMUX_GPIO143__FUNC_GPIO143>;
			output-low;
		};

		pins-cmd-dat1 {
			pinmux = <PINMUX_GPIO144__FUNC_GPIO144>,
				<PINMUX_GPIO145__FUNC_GPIO145>;
			bias-pull-up;
			input-enable;
		};
	};

	pcie0_pins_work: pcie0-work {
		pins-cmd-dat {
			pinmux = <PINMUX_GPIO143__FUNC_PCIE_PERSTN>,
				<PINMUX_GPIO145__FUNC_PCIE_CLKREQN>;
			bias-pull-up;
		};

		pins-cmd-dat1 {
			pinmux = <PINMUX_GPIO144__FUNC_GPIO144>;
			bias-pull-down;
			input-enable;
		};
	};

	pcie0_pins_sleep: pcie0-sleep {
		pins-cmd-dat {
			pinmux = <PINMUX_GPIO143__FUNC_GPIO143>;
			output-low;
		};

		pins-cmd-dat1 {
			pinmux = <PINMUX_GPIO144__FUNC_GPIO144>,
				 <PINMUX_GPIO145__FUNC_GPIO145>;
			bias-pull-up;
			input-enable;
		};
	};

	pcie1_pins_default: pcie1-default {
		pins-cmd-dat {
			pinmux = <PINMUX_GPIO2__FUNC_PCIE_CLKREQN_P1>,
				 <PINMUX_GPIO4__FUNC_PCIE_PERSTN_P1>;
			bias-pull-up;
		};
	};
};
/* PCIe pinmux end */

#if 0
/* GPS GPIO standardization start */
&pio {
	gps_pins_default: gps_default {
	};
	gps_l1_lna_pins_ol: gps-l1-lna0 {
		pins-cmd-dat {
			pinmux = <PINMUX_GPIO12__FUNC_GPIO12>;
			output-low;
		};
	};
	gps_l1_lna_pins_dsp_ctrl: gps-l1-lna1 {
		pins-cmd-dat {
			pinmux = <PINMUX_GPIO12__FUNC_GPS_L1_ELNA_EN>;
		};
	};
	gps_l1_lna_pins_oh: gps-l1-lna2 {
		pins-cmd-dat {
			pinmux = <PINMUX_GPIO12__FUNC_GPIO12>;
			output-high;
		};
	};
	gps_l5_lna_pins_ol: gps-l5-lna0 {
		pins-cmd-dat {
			pinmux = <PINMUX_GPIO13__FUNC_GPIO13>;
			output-low;
		};
	};
	gps_l5_lna_pins_dsp_ctrl: gps-l5-lna1 {
		pins-cmd-dat {
			pinmux = <PINMUX_GPIO13__FUNC_GPS_L5_ELNA_EN>;
		};
	};
	gps_l5_lna_pins_oh: gps-l5-lna2 {
		pins-cmd-dat {
			pinmux = <PINMUX_GPIO13__FUNC_GPIO13>;
			output-high;
		};
	};
};
&gps {
	pinctrl-names = "default",
		"gps_l1_lna_disable",
		"gps_l1_lna_dsp_ctrl",
		"gps_l1_lna_enable",
		"gps_l5_lna_disable",
		"gps_l5_lna_dsp_ctrl",
		"gps_l5_lna_enable";
	pinctrl-0 = <&gps_pins_default>;
	pinctrl-1 = <&gps_l1_lna_pins_ol>;
	pinctrl-2 = <&gps_l1_lna_pins_dsp_ctrl>;
	pinctrl-3 = <&gps_l1_lna_pins_oh>;
	pinctrl-4 = <&gps_l5_lna_pins_ol>;
	pinctrl-5 = <&gps_l5_lna_pins_dsp_ctrl>;
	pinctrl-6 = <&gps_l5_lna_pins_oh>;
	status = "okay";
};
/* GPS GPIO standardization end */
#endif

/* usb typec mux start */
&pio {

	ps_enable: ps_enable {
		pins_cmd_dat {
//			pinmux = <PINMUX_GPIO111__FUNC_GPIO111>;
//			output-high;
		};
	};

	ps_disable: ps_disable {
		pins_cmd_dat {
//			pinmux = <PINMUX_GPIO111__FUNC_GPIO111>;
//			output-low;
		};
	};

};

&mt6375_typec {
	port {
		tcpc_typec_usb: endpoint {
			remote-endpoint = <&ssusb_mux>;
		};
	};
};

&typec_mux_switch {
	orientation-switch;
	mode-switch;
	accessory;
	port {
		ssusb_mux: endpoint {
			remote-endpoint = <&tcpc_typec_usb>;
		};
	};
};

&ps5170 {
	pinctrl-names = "enable", "disable";
	pinctrl-0 = <&ps_enable>;
	pinctrl-1 = <&ps_disable>;
	status = "okay";
};

&usb_dp_selector {
	status = "okay";
};
/* usb typec mux end */

#if 0
&pdc {
	pd_vbus_upper_bound = <12000000>;
};
#endif

&i2c6 {
	spk1: speaker_amp@5c {
		compatible = "richtek,rt5512";
		#sound-dai-cells = <0>;
		reg = <0x5c>;
		status = "okay";
		sound-name-prefix = "Left";
	};

	spk2: speaker_amp@5d {
		compatible = "richtek,rt5512";
		#sound-dai-cells = <0>;
		reg = <0x5d>;
		status = "okay";
		sound-name-prefix = "Right";
	};
};

&sound {
	mediatek,spk-i2s = <25 24>;
	mediatek,speaker-codec {
		sound-dai = <&spk1>, <&spk2>;
	};
};

&odm {
/*OPLUS_FEATURE_OEM_OCDT oppo project start */
	oplus_project:oplus_project {
		compatible = "oplus,oplus_project";
	};

    oplus_boardid:oplus_boardid {
		compatible = "oplus,oplus_boardid-v2";
		support-dtsino=<24610>;//only one u32
		/*first one is low 32bit, last one is highest 32bit, must be 32-bit for 4gpios*/
		support-pcbmask=<0xffffffff 0xffffffff 0xffffffff>;
	};

        oplus_devinfo:oplus_devinfo {
		compatible = "oplus-devinfo";
		pinctrl-names = "default", "aboard_gpio0_sleep", "aboard_gpio0_active", "aboard_gpio0_idle";
		pinctrl-0 = <&hw_pins_default>;
		pinctrl-1 = <&aboard_pin_gpio0_sleep>;
		pinctrl-2 = <&aboard_pin_gpio0_active>;
		pinctrl-3 = <&aboard_pin_gpio0_idle>;
		main-sub {
			use_tristate_gpio;
			compatible = "hw-match, main-sub";
			aboard-gpio0 = <&pio 126 0x00>;
			aboard-patterns = <0 1>;        /*0[high-resistance] 1[pull-down] 2[pull-up]*/
			/*main board*/
			match-projects = <24610 24610>;
		};
	};

	kpd_volume_down:kpd_volume_down {
		compatible = "mediatek, VOLUME_DOWN-eint";
		interrupt-parent = <&pio>;
		interrupts = <11 IRQ_TYPE_EDGE_FALLING 11 0>;
		debounce = <32000>;
		status = "okay";
	};

	pmic_history_count:pmic_history_count {
	};
	pmic_history0:pmic_history0 {
	};
	pmic_history1:pmic_history1 {
	};
	pmic_history2:pmic_history2 {
	};
	pmic_history3:pmic_history3 {
	};

};
&pio{
        hw_pins_default:default@hw_sub_id {
	};

        aboard_pin_gpio0_sleep:sleep@id0 {
		pins_cmd_dat {
			pinmux = <PINMUX_GPIO126__FUNC_GPIO126>;
			slew-rate = <0>;
			bias-pull-down;
			input-enable;
		};
	};

	aboard_pin_gpio0_active:active@id0 {
		pins_cmd_dat {
			pinmux = <PINMUX_GPIO126__FUNC_GPIO126>;
			slew-rate = <0>;
			bias-pull-up;
			input-enable;
		};
	};

	aboard_pin_gpio0_idle:idle@id0 {
		pins_cmd_dat {
			pinmux = <PINMUX_GPIO126__FUNC_GPIO126>;
			slew-rate = <0>;
			bias-disable;
			input-enable;
		};
	};

    //#ifdef OPLUS_VENDOR_SWTP
    swtp: swtp {
        compatible = "mediatek, swtp-eint";
    };
    swtp_1: swtp_1 {
        compatible = "mediatek, swtp1-eint";
    };
    //#endif  /*OPLUS_VENDOR_SWTP*/

};

&wifi {
	flavor-bin = "dx3";
};

&bt {
	flavor-bin = "dx3";
};

&mt6363_vbuck5 {
	regulator-always-on;
};

&mt6363_vbuck6 {
	regulator-always-on;
};

&mt6363_vsram_digrf {
	regulator-always-on;
};

&mt6363_vsram_modem {
	regulator-always-on;
};

&mt6363_vcn15 {
	regulator-always-on;
};

&mmlsys_config {
	dl-enable;
};

&soc {
	oplus,f2fs {
		seqzone {
			switch = "supported";
		};
	};

	//Kernel.Storage, 2024/10/9, add for blk-mq.c block_graded_thread_enable
	oplus,blk-mq {
		block_graded_thread_enable = "y";
	};
};

&low_battery_throttling {
	thd-volts-l = <
			3698 3524 3356
			3839 3644 3456
			4093 3862 3636
			4400 4139 3784>;
	thd-volts-h = <
			3798 3698 3524
			3939 3839 3644
			4193 4093 3862
			4500 4400 4139>;
	thd-volts-l-2s = <
			3698 3524 3356
			3839 3644 3456
			4093 3862 3636
			4400 4139 3784>;
	thd-volts-h-2s = <
			3798 3698 3524
			3939 3839 3644
			4193 4093 3862
			4500 4400 4139>;
};

&peak_power_budget {
	battery0-path-rdc-t0 = <103>;
	battery0-path-rac-t0 = <68>;
	battery0-path-rdc-t1 = <135>;
	battery0-path-rac-t1 = <68>;
	battery0-path-rdc-t2 = <197>;
	battery0-path-rac-t2 = <68>;
	battery0-path-rdc-t3 = <397>;
	battery0-path-rac-t3 = <68>;

	bat-ocv-table-num = <5>;

	bat0-ocv-table-t0-temperature = <50>;
	bat0-ocv-table-t0-qmax = <6948>;
	bat0-ocv-table-t0-size = <100>;
	bat0-ocv-table-t0 = <
		0       44828   0
		719     44597   0
		1438    44430   0
		2156    44298   0
		2875    44184   0
		3594    44074   0
		4313    43968   0
		5031    43860   0
		5750    43754   0
		6469    43642   0
		7188    43530   0
		7906    43418   0
		8625    43300   0
		9344    43184   0
		10063   43065   0
		10781   42937   0
		11500   42816   0
		12219   42688   0
		12938   42561   0
		13656   42434   0
		14375   42306   0
		15094   42171   0
		15813   42042   0
		16531   41914   0
		17250   41786   0
		17969   41664   0
		18688   41537   0
		19407   41418   0
		20125   41298   0
		20844   41173   0
		21563   41057   0
		22282   40941   0
		23000   40830   0
		23719   40718   0
		24438   40605   0
		25157   40495   0
		25875   40392   0
		26594   40288   0
		27313   40186   0
		28032   40092   0
		28750   39992   0
		29469   39894   0
		30188   39787   0
		30907   39660   0
		31625   39488   0
		32344   39330   0
		33063   39220   0
		33782   39128   0
		34501   39049   0
		35219   38971   0
		35938   38896   0
		36657   38826   0
		37376   38767   0
		38094   38705   0
		38813   38643   0
		39532   38583   0
		40251   38526   0
		40969   38476   0
		41688   38421   0
		42407   38372   0
		43126   38326   0
		43844   38278   0
		44563   38237   0
		45282   38193   0
		46001   38155   0
		46719   38114   0
		47438   38078   0
		48157   38041   0
		48876   37995   0
		49594   37950   0
		50313   37868   0
		51032   37779   0
		51751   37704   0
		52470   37655   0
		53188   37599   0
		53907   37544   0
		54626   37490   0
		55345   37444   0
		56063   37395   0
		56782   37351   0
		57501   37302   0
		58220   37235   0
		58938   37159   0
		59657   37092   0
		60376   37025   0
		61095   36933   0
		61813   36875   0
		62532   36859   0
		63251   36848   0
		63970   36826   0
		64688   36808   0
		65407   36767   0
		66126   36619   0
		66845   36235   0
		67564   35698   0
		68282   34998   0
		69001   34011   0
		69720   32471   0
		70439   32471   0
		71157   32471   0>;

	bat0-ocv-table-t1-temperature = <25>;
	bat0-ocv-table-t1-qmax = <7090>;
	bat0-ocv-table-t1-size = <100>;
	bat0-ocv-table-t1 = <
		0       44934   0
		719     44701   0
		1438    44536   0
		2156    44405   0
		2875    44289   0
		3594    44185   0
		4313    44078   0
		5031    43962   0
		5750    43856   0
		6469    43751   0
		7188    43639   0
		7906    43529   0
		8625    43412   0
		9344    43310   0
		10063   43193   0
		10781   43069   0
		11500   42946   0
		12219   42820   0
		12938   42695   0
		13656   42566   0
		14375   42438   0
		15094   42310   0
		15813   42179   0
		16531   42048   0
		17250   41927   0
		17969   41799   0
		18688   41669   0
		19407   41548   0
		20125   41422   0
		20844   41303   0
		21563   41187   0
		22282   41068   0
		23000   40951   0
		23719   40843   0
		24438   40728   0
		25157   40622   0
		25875   40513   0
		26594   40409   0
		27313   40309   0
		28032   40202   0
		28750   40102   0
		29469   40002   0
		30188   39901   0
		30907   39793   0
		31625   39673   0
		32344   39523   0
		33063   39361   0
		33782   39229   0
		34501   39130   0
		35219   39039   0
		35938   38967   0
		36657   38896   0
		37376   38830   0
		38094   38767   0
		38813   38706   0
		39532   38650   0
		40251   38590   0
		40969   38536   0
		41688   38485   0
		42407   38434   0
		43126   38389   0
		43844   38345   0
		44563   38297   0
		45282   38257   0
		46001   38218   0
		46719   38185   0
		47438   38147   0
		48157   38108   0
		48876   38078   0
		49594   38044   0
		50313   38001   0
		51032   37967   0
		51751   37923   0
		52470   37871   0
		53188   37815   0
		53907   37770   0
		54626   37716   0
		55345   37662   0
		56063   37614   0
		56782   37580   0
		57501   37535   0
		58220   37493   0
		58938   37441   0
		59657   37373   0
		60376   37307   0
		61095   37232   0
		61813   37163   0
		62532   37070   0
		63251   37007   0
		63970   36991   0
		64688   36975   0
		65407   36956   0
		66126   36936   0
		66845   36898   0
		67564   36780   0
		68282   36403   0
		69001   35859   0
		69720   35131   0
		70439   34082   0
		71157   32223   0>;

	bat0-ocv-table-t2-temperature = <10>;
	bat0-ocv-table-t2-qmax = <7056>;
	bat0-ocv-table-t2-size = <100>;
	bat0-ocv-table-t2 = <
		0       44822   0
		719     44608   0
		1438    44459   0
		2156    44332   0
		2875    44228   0
		3594    44128   0
		4313    44021   0
		5031    43921   0
		5750    43821   0
		6469    43707   0
		7188    43601   0
		7906    43495   0
		8625    43378   0
		9344    43260   0
		10063   43146   0
		10781   43019   0
		11500   42895   0
		12219   42767   0
		12938   42638   0
		13656   42509   0
		14375   42380   0
		15094   42247   0
		15813   42122   0
		16531   41987   0
		17250   41866   0
		17969   41735   0
		18688   41609   0
		19407   41484   0
		20125   41361   0
		20844   41240   0
		21563   41122   0
		22282   41004   0
		23000   40889   0
		23719   40780   0
		24438   40664   0
		25157   40557   0
		25875   40450   0
		26594   40344   0
		27313   40245   0
		28032   40143   0
		28750   40036   0
		29469   39942   0
		30188   39829   0
		30907   39716   0
		31625   39579   0
		32344   39417   0
		33063   39271   0
		33782   39157   0
		34501   39062   0
		35219   38974   0
		35938   38902   0
		36657   38828   0
		37376   38765   0
		38094   38697   0
		38813   38640   0
		39532   38573   0
		40251   38522   0
		40969   38467   0
		41688   38416   0
		42407   38370   0
		43126   38325   0
		43844   38275   0
		44563   38233   0
		45282   38193   0
		46001   38154   0
		46719   38114   0
		47438   38080   0
		48157   38047   0
		48876   38013   0
		49594   37985   0
		50313   37946   0
		51032   37919   0
		51751   37886   0
		52470   37852   0
		53188   37812   0
		53907   37767   0
		54626   37717   0
		55345   37661   0
		56063   37617   0
		56782   37582   0
		57501   37543   0
		58220   37493   0
		58938   37429   0
		59657   37359   0
		60376   37295   0
		61095   37234   0
		61813   37151   0
		62532   37059   0
		63251   37011   0
		63970   36989   0
		64688   36972   0
		65407   36951   0
		66126   36911   0
		66845   36852   0
		67564   36668   0
		68282   36216   0
		69001   35560   0
		69720   34644   0
		70439   33562   0
		71157   33562   0>;

	bat0-ocv-table-t3-temperature = <0>;
	bat0-ocv-table-t3-qmax = <6803>;
	bat0-ocv-table-t3-size = <100>;
	bat0-ocv-table-t3 = <
		0       44869   0
		719     44628   0
		1438    44472   0
		2156    44353   0
		2875    44248   0
		3594    44150   0
		4313    44056   0
		5031    43958   0
		5750    43858   0
		6469    43758   0
		7188    43652   0
		7906    43543   0
		8625    43433   0
		9344    43317   0
		10063   43201   0
		10781   43084   0
		11500   42958   0
		12219   42833   0
		12938   42705   0
		13656   42578   0
		14375   42450   0
		15094   42319   0
		15813   42188   0
		16531   42060   0
		17250   41932   0
		17969   41806   0
		18688   41679   0
		19407   41554   0
		20125   41429   0
		20844   41308   0
		21563   41187   0
		22282   41068   0
		23000   40950   0
		23719   40837   0
		24438   40720   0
		25157   40609   0
		25875   40500   0
		26594   40390   0
		27313   40284   0
		28032   40181   0
		28750   40072   0
		29469   39963   0
		30188   39846   0
		30907   39721   0
		31625   39606   0
		32344   39444   0
		33063   39306   0
		33782   39188   0
		34501   39086   0
		35219   38997   0
		35938   38916   0
		36657   38841   0
		37376   38771   0
		38094   38706   0
		38813   38641   0
		39532   38582   0
		40251   38524   0
		40969   38469   0
		41688   38415   0
		42407   38365   0
		43126   38316   0
		43844   38270   0
		44563   38223   0
		45282   38184   0
		46001   38139   0
		46719   38100   0
		47438   38063   0
		48157   38028   0
		48876   37994   0
		49594   37962   0
		50313   37930   0
		51032   37901   0
		51751   37876   0
		52470   37845   0
		53188   37817   0
		53907   37787   0
		54626   37741   0
		55345   37705   0
		56063   37659   0
		56782   37611   0
		57501   37572   0
		58220   37524   0
		58938   37467   0
		59657   37397   0
		60376   37325   0
		61095   37257   0
		61813   37184   0
		62532   37088   0
		63251   36995   0
		63970   36945   0
		64688   36904   0
		65407   36861   0
		66126   36799   0
		66845   36707   0
		67564   36513   0
		68282   36259   0
		69001   36259   0
		69720   36259   0
		70439   36259   0
		71157   36259   0>;

	bat-ocv-table-t4-temperature = <(-10)>;
	bat-ocv-table-t4-qmax = <6535>;
	bat-ocv-table-t4-size = <100>;
	bat-ocv-table-t4 = <
		0       44853   0
		719     44575   0
		1438    44397   0
		2156    44258   0
		2875    44146   0
		3594    44034   0
		4313    43933   0
		5031    43833   0
		5750    43732   0
		6469    43631   0
		7188    43524   0
		7906    43418   0
		8625    43311   0
		9344    43195   0
		10063   43083   0
		10781   42971   0
		11500   42848   0
		12219   42725   0
		12938   42602   0
		13656   42473   0
		14375   42349   0
		15094   42221   0
		15813   42091   0
		16531   41966   0
		17250   41835   0
		17969   41711   0
		18688   41582   0
		19407   41458   0
		20125   41335   0
		20844   41212   0
		21563   41089   0
		22282   40972   0
		23000   40853   0
		23719   40733   0
		24438   40612   0
		25157   40499   0
		25875   40388   0
		26594   40268   0
		27313   40152   0
		28032   40036   0
		28750   39914   0
		29469   39786   0
		30188   39652   0
		30907   39521   0
		31625   39392   0
		32344   39275   0
		33063   39164   0
		33782   39062   0
		34501   38969   0
		35219   38885   0
		35938   38807   0
		36657   38734   0
		37376   38657   0
		38094   38594   0
		38813   38535   0
		39532   38474   0
		40251   38418   0
		40969   38366   0
		41688   38308   0
		42407   38256   0
		43126   38207   0
		43844   38138   0
		44563   38099   0
		45282   38058   0
		46001   38015   0
		46719   37998   0
		47438   37964   0
		48157   37924   0
		48876   37897   0
		49594   37866   0
		50313   37844   0
		51032   37821   0
		51751   37798   0
		52470   37771   0
		53188   37745   0
		53907   37711   0
		54626   37678   0
		55345   37633   0
		56063   37576   0
		56782   37519   0
		57501   37480   0
		58220   37416   0
		58938   37343   0
		59657   37269   0
		60376   37192   0
		61095   37111   0
		61813   37010   0
		62532   36903   0
		63251   36824   0
		63970   36754   0
		64688   36697   0
		65407   36607   0
		66126   36607   0
		66845   36607   0
		67564   36607   0
		68282   36607   0
		69001   36607   0
		69720   36607   0
		70439   36607   0
		71157   36607   0>;
};

#include <oplus6989_24610/cust.dtsi>
#include "mediatek/cust_k6989_connfem.dtsi"
#include "mediatek/cust_mt6989_touch_1080x2400.dtsi"
#include "mediatek/cust_mt6989_caymana_camera_v4l2.dtsi"
#include "mediatek/cust_mt6989_24610_audio.dtsi"
/*End of this file, DO NOT ADD ANYTHING HERE*/
